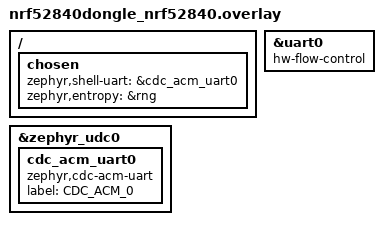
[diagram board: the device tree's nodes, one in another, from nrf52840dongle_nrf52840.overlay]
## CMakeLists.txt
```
# SPDX-License-Identifier: Apache-2.0

cmake_minimum_required(VERSION 3.20.0)
find_package(Zephyr REQUIRED HINTS $ENV{ZEPHYR_BASE})
project(openthread_cli)

target_sources(app PRIVATE src/main.c)
```

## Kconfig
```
menu "Zephyr Kernel"
    source "Kconfig.zephyr"
    endmenu
    
    module = OT_COMMAND_LINE_INTERFACE
    module-str = ot_cli
    source "${ZEPHYR_BASE}/subsys/logging/Kconfig.template.log_config"
    
```

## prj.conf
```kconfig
CONFIG_OPENTHREAD_NORDIC_LIBRARY_FTD=y
CONFIG_NET_L2_OPENTHREAD=y
CONFIG_NETWORKING=y
CONFIG_OPENTHREAD_MANUAL_START=n
CONFIG_OPENTHREAD_NETWORK_NAME="TEST_1"
CONFIG_OPENTHREAD_PANID=10000
CONFIG_OPENTHREAD_XPANID="fb:02:00:00:ab:cd:00:00"
CONFIG_OPENTHREAD_NETWORKKEY="00:11:22:33:44:55:66:77:88:99:aa:bb:cc:dd:ee:ff"
CONFIG_SHELL=y
CONFIG_OPENTHREAD_SHELL=y
CONFIG_SHELL_ARGC_MAX=26
CONFIG_SHELL_CMD_BUFF_SIZE=416
CONFIG_MBEDTLS_SHA1_C=n 
CONFIG_FPU=y


#CONFIG_USB_DEVICE_PRODUCT="TESTING"
#CONFIG_USB_DEVICE_INITIALIZE_AT_BOOT=y

#CONFIG_USB_NRFX=y
#CONFIG_USB_DEVICE_DRIVER=y
#CONFIG_NRFX_USBD=y

CONFIG_OPENTHREAD=y
CONFIG_USB_DEVICE_STACK=y
CONFIG_USB_DEVICE_PRODUCT="Zephyr USB console sample"

CONFIG_SERIAL=y
CONFIG_CONSOLE=y
CONFIG_UART_CONSOLE=y
CONFIG_UART_LINE_CTRL=y
CONFIG_USB_CDC_ACM=y




CONFIG_SHELL_BACKEND_SERIAL_INIT_PRIORITY=51
CONFIG_SHELL_BACKEND_SERIAL_CHECK_DTR=y
CONFIG_USB_CDC_ACM_LOG_LEVEL_OFF=n
CONFIG_USB_DEVICE_REMOTE_WAKEUP=n
CONFIG_OPENTHREAD_NORDIC_LIBRARY_MASTER=y
CONFIG_ASSERT=y
CONFIG_ASSERT_NO_COND_INFO=y
CONFIG_GPIO_SHELL=y
CONFIG_LOG=y
CONFIG_LOG_MODE_MINIMAL=n
CONFIG_LOG_MAX_LEVEL=3



# Use separate thread for logging
CONFIG_LOG_MODE_DEFERRED=y


# Option for configuring log level in this sample
#CONFIG_OT_COMMAND_LINE_INTERFACE_LOG_LEVEL_INF=y

# Enable net module logging
# CONFIG_NET_LOG=y
# Option for configuring log level in net config library
# CONFIG_NET_CONFIG_LOG_LEVEL_INF=y

# Option for configuring log level in Zephyr L2 logging
# CONFIG_OPENTHREAD_L2_DEBUG=y
# CONFIG_OPENTHREAD_L2_LOG_LEVEL_DBG=y
# CONFIG_OPENTHREAD_L2_DEBUG_DUMP_15_4=y
# CONFIG_OPENTHREAD_L2_DEBUG_DUMP_IPV6=y

# Enable OpenThread logging
CONFIG_OPENTHREAD_DEBUG=y
# Option for configuring log level in OpenThread
CONFIG_OPENTHREAD_LOG_LEVEL_INFO=y
```

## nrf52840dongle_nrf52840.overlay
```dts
// / {
// 	chosen {
// 		zephyr,console = &cdc_acm_uart0;
// 	};
// };
/ {
	chosen {
		zephyr,shell-uart = &cdc_acm_uart0;
	};
};

&zephyr_udc0 {
	cdc_acm_uart0: cdc_acm_uart0 {
		compatible = "zephyr,cdc-acm-uart";
		label = "CDC_ACM_0";
	};
};

&uart0 {
	status = "okay";
	hw-flow-control;
};

/ {
	chosen {
		zephyr,entropy = &rng;
	};
};
```

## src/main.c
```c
#include <zephyr/kernel.h>
#include <zephyr/logging/log.h>
#include <zephyr/drivers/uart.h>
#include <zephyr/usb/usb_device.h>
#include <zephyr/sys/printk.h>

LOG_MODULE_REGISTER(cli_sample, CONFIG_OT_COMMAND_LINE_INTERFACE_LOG_LEVEL);



void main(void)
{
	int ret;
	const struct device *dev;
	uint32_t dtr = 0U;

	ret = usb_enable(NULL);
	if (ret != 0) {
		printk("Failed to enable USB");
		return;
	}

	dev = DEVICE_DT_GET(DT_CHOSEN(zephyr_shell_uart));
	if (dev == NULL) {
		printk("Failed to find specific UART device");
		return;
	}

	printk("Waiting for host to be ready to communicate");

	/* Data Terminal Ready - check if host is ready to communicate */
	while (!dtr) {
		ret = uart_line_ctrl_get(dev, UART_LINE_CTRL_DTR, &dtr);
		if (ret) {
			printk("Failed to get Data Terminal Ready line state: %d",
				ret);
			continue;
		}
		k_msleep(100);
	}
	while(1){
		printk("It works!\n");
		printk("It does!\n");
		k_msleep(1000);
	}
	/* Data Carrier Detect Modem - mark connection as established */
	(void)uart_line_ctrl_set(dev, UART_LINE_CTRL_DCD, 1);
	/* Data Set Ready - the NCP SoC is ready to communicate */
	(void)uart_line_ctrl_set(dev, UART_LINE_CTRL_DSR, 1);
}
```
